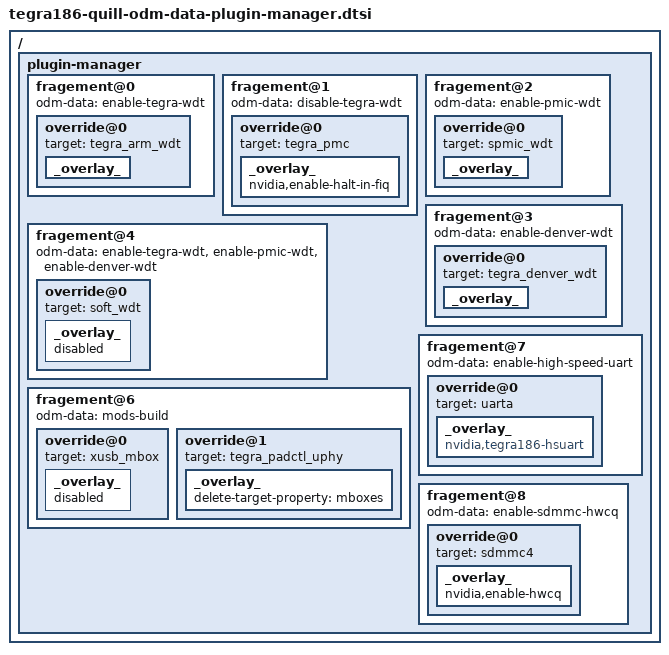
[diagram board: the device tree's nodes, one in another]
/*
 * tegra186-quill-p3310-1000-a00-plugin-manager.dtsi: P3310 plugin manager
 *
 * Copyright (c) 2015, NVIDIA CORPORATION.  All rights reserved.
 *
 * This program is free software; you can redistribute it and/or modify
 * it under the terms of the GNU General Public License as published by
 * the Free Software Foundation; version 2 of the License.
 *
 * This program is distributed in the hope that it will be useful, but WITHOUT
 * ANY WARRANTY; without even the implied warranty of MERCHANTABILITY or
 * FITNESS FOR A PARTICULAR PURPOSE.  See the GNU General Public License for
 * more details.
 */

/ {
	plugin-manager {
		fragement@0 {
			odm-data = "enable-tegra-wdt";
			override@0 {
				target = <&tegra_arm_wdt>;
				_overlay_ {
					status = "okay";
				};
			};
		};

		fragement@1 {
			odm-data = "disable-tegra-wdt";
			override@0 {
				target = <&tegra_pmc>;
				_overlay_ {
					nvidia,enable-halt-in-fiq;
				};
			};
		};

		fragement@2 {
			odm-data = "enable-pmic-wdt";
			override@0 {
				target = <&spmic_wdt>;
				_overlay_ {
					status = "okay";
				};
			};
		};

		fragement@3 {
			odm-data = "enable-denver-wdt";
			override@0 {
				target = <&tegra_denver_wdt>;
				_overlay_ {
					status = "okay";
				};
			};
		};

		fragement@4 {
			odm-data = "enable-tegra-wdt",
					"enable-pmic-wdt",
					"enable-denver-wdt";
			override@0 {
				target = <&soft_wdt>;
				_overlay_ {
					status = "disabled";
				};
			};
		};

		fragement@6 {
			odm-data = "mods-build";
			override@0 {
				target = <&xusb_mbox>;
				_overlay_ {
					status = "disabled";
				};
			};
			override@1 {
				target = <&tegra_padctl_uphy>;
				_overlay_ {
					delete-target-property = "mboxes";
				};
			};
		};

		fragement@7 {
			odm-data = "enable-high-speed-uart";
			override@0 {
				target = <&uarta>;
				_overlay_ {
					compatible = "nvidia,tegra186-hsuart";
				};
			};
		};

		fragement@8 {
			odm-data = "enable-sdmmc-hwcq";
			override@0 {
				target = <&sdmmc4>;
				_overlay_ {
					nvidia,enable-hwcq;
				};
			};
		};
	};
};
